# AT32A403Axx_v2 register map
Vendor: Keil; Series: AT32A403A; File version: 1.0
CPU: CM4 r0p1, little endian, no MPU, FPU, 4 interrupt priority bits
Registers are 32-bit, read-write, reset 0x0 unless marked. A register's access mark holds for its fields unless they carry their own. Offsets are from the block's base; [hi:lo] are bit positions; {n}, {i} and the like mark numbered series.

## NVIC — Nested Vectored Interrupt Controller
Base 0xE000E000
0x04 ICTR ro — Interrupt Controller Type Register
  [3:0] INTLINESNUM — Total number of interrupt lines in groups
0x100 ISER0 — Interrupt Set-Enable Register
  [31:0] SETENA
0x104 ISER1 — Interrupt Set-Enable Register
  [31:0] SETENA
0x180 ICER0 — Interrupt Clear-Enable Register
  [31:0] CLRENA
0x184 ICER1 — Interrupt Clear-Enable Register
  [31:0] CLRENA
0x200 ISPR0 — Interrupt Set-Pending Register
  [31:0] SETPEND
0x204 ISPR1 — Interrupt Set-Pending Register
  [31:0] SETPEND
0x280 ICPR0 — Interrupt Clear-Pending Register
  [31:0] CLRPEND
0x284 ICPR1 — Interrupt Clear-Pending Register
  [31:0] CLRPEND
0x300 IABR0 ro — Interrupt Active Bit Register
  [31:0] ACTIVE
0x304 IABR1 ro — Interrupt Active Bit Register
  [31:0] ACTIVE
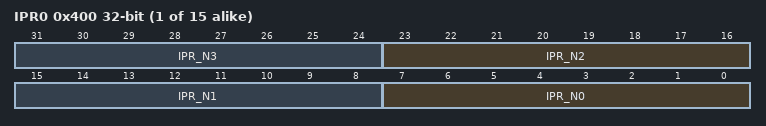
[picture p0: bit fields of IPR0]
{0x400+4i} IPR{i} (i=0..14) — Interrupt Priority Register
  [8n+7:8n] IPR_N{n} (n=0..3)
0xF00 STIR wo — Software Triggered Interrupt Register
  [8:0] INTID — interrupt to be triggered

## USBFS — Universal serial bus full-speed device interface
Base 0x40005C00
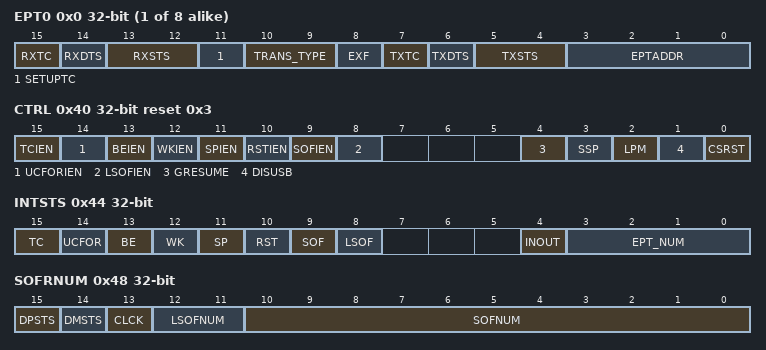
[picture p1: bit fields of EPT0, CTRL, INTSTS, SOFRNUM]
{0x0+4i} EPT{i} (i=0..7) — endpoint {i} register
  [15] RXTC — Rx transaction completed
  [14] RXDTS — Rx data toggle synchronization
  [13:12] RXSTS — Rx Status
  [11] SETUPTC — Setup transaction completed
  [10:9] TRANS_TYPE — Transfer type
  [8] EXF — Endpoint extend function
  [7] TXTC — Tx transaction completed
  [6] TXDTS — Tx data toggle synchronization
  [5:4] TXSTS — Tx status
  [3:0] EPTADDR — Endpoint address
0x40 CTRL reset 0x3 — control register
  [15] TCIEN — transmission completed interrupt enable
  [14] UCFORIEN — USB Core fifo overrun interrupt enable
  [13] BEIEN — Bus error interrupt enable
  [12] WKIEN — Wakeup/Remote wakeup interrupt enable
  [11] SPIEN — Bus suspend mode interrupt enable
  [10] RSTIEN — Bus reset interrupt enable
  [9] SOFIEN — Start of frame interrupt enable
  [8] LSOFIEN — Lost start of frame interrupt enable
  [4] GRESUME — Generate resume request
  [3] SSP — Soft suspend config
  [2] LPM — Low power mode
  [1] DISUSB — Disable usb phy
  [0] CSRST — Core soft reset
0x44 INTSTS — interrupt status register
  [15] TC — transaction completed
  [14] UCFOR — USB core fifo overrun memory
  [13] BE — Bus error
  [12] WK — Wakeup
  [11] SP — Bus suspend
  [10] RST — Bus reset
  [9] SOF — start of frame
  [8] LSOF — Lost start of frame
  [4] INOUT — In/Out transaction
  [3:0] EPT_NUM — Endpoint number
0x48 SOFRNUM — frame number register
  [15] DPSTS — DP status
  [14] DMSTS — DM status
  [13] CLCK — Connect locked
  [12:11] LSOFNUM — Lost start of frame number
  [10:0] SOFNUM — Start of frame number
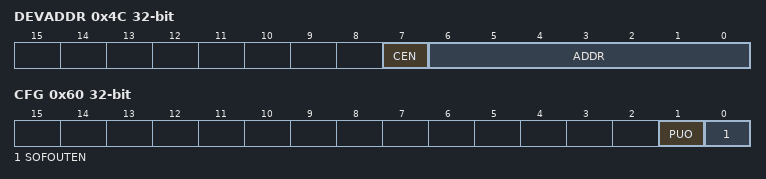
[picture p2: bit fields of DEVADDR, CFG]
0x4C DEVADDR — device address
  [7] CEN — USB core enable
  [6:0] ADDR — Host assign device address
0x50 BUFTBL — Buffer table address
  [15:3] BTADDR — Endpoint buffer table start address
0x60 CFG — CFG control register
  [1] PUO — DP pullup off
  [0] SOFOUTEN — SOF output enable

## ETHERNET_MMC — Ethernet: MAC management counters
Base 0x40028100
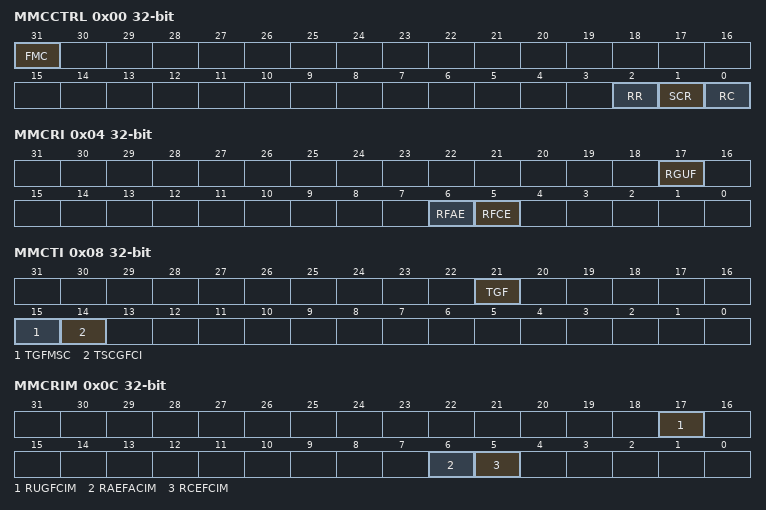
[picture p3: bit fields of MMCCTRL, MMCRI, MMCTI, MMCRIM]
0x00 MMCCTRL — Ethernet MMC control register
  [31] FMC — Freeze MMC counter
  [2] RR — Reset on read
  [1] SCR — Stop counter rollover
  [0] RC — Reset counter
0x04 MMCRI — Ethernet MMC receive interrupt register
  [17] RGUF — Received good unicast frames
  [6] RFAE — Received frames alignment error
  [5] RFCE — Received frames CRC error
0x08 MMCTI — Ethernet MMC transmit interrupt register
  [21] TGF — Transmitted good frames
  [15] TGFMSC — Transmit good frames more single collision
  [14] TSCGFCI — Transmit single collision good frame counter interrupt
0x0C MMCRIM — Ethernet MMC receive interrupt mask register
  [17] RUGFCIM — Received unicast good frame counter interrupt mask
  [6] RAEFACIM — Received alignment error frame alignment counter interrupt mask
  [5] RCEFCIM — Received CRC error frame counter interrupt mask
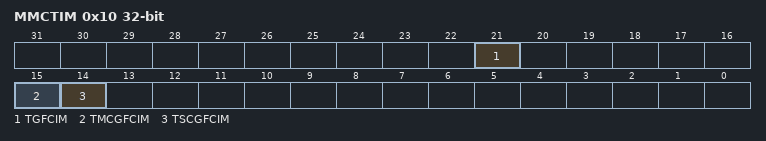
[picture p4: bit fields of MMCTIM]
0x10 MMCTIM — Ethernet MMC transmit interrupt mask register
  [21] TGFCIM — Transmitted good frame counter interrupt mask
  [15] TMCGFCIM — Transmit multiple collision good frame counter interrupt mask
  [14] TSCGFCIM — Transmit single collision good frame counter interrupt mask
0x4C MMCTFSCC ro — Ethernet MMC transmitted good frames after a single collision counter
  [31:0] TGFSCC — Transmitted good frames single collision counter
0x50 MMCTFMSCC ro — Ethernet MMC transmitted good frames after more than a single collision
  [31:0] TGFMSCC — Transmitted good frame more single collision counter
0x68 MMCTFCNT ro — Ethernet MMC transmitted good frames counter register
  [31:0] TGFC — Transmitted good frames counter
0x94 MMCRFCECNT ro — Ethernet MMC received frames with CRC error counter register
  [31:0] RFCEC — Received frames CRC error counter
0x98 MMCRFAECNT ro — Ethernet MMC received frames with alignment error counter register
  [31:0] RFAEC — Received frames alignment error counter
0xC4 MMCRGUFCNT ro — MMC received good unicast frames counter register
  [31:0] RGUFC — Received good unicast frames counter

## ETHERNET_PTP — Ethernet: Precision time protocol
Base 0x40028700
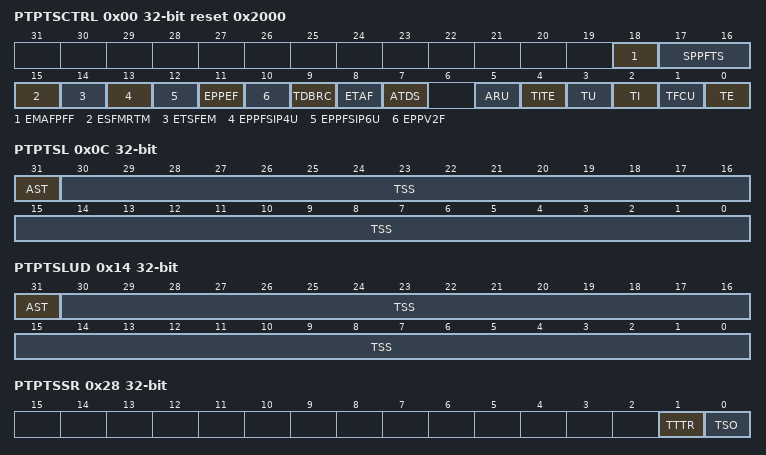
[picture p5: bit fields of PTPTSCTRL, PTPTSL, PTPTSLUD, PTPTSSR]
0x00 PTPTSCTRL reset 0x2000 — Ethernet PTP time stamp control register
  [18] EMAFPFF — Enable MAC address for PTP frame filtering
  [17:16] SPPFTS — Select PTP packet for taking snapshot
  [15] ESFMRTM — Enable snapshot for message relevant to master
  [14] ETSFEM — Enable timestamp snapshot for event message
  [13] EPPFSIP4U — Enable processing of PTP frames sent over IPv4-UDP
  [12] EPPFSIP6U — Enable processing of PTP frames sent over IPv6-UDP
  [11] EPPEF — Enable processing of PTP over EMAC frames
  [10] EPPV2F — Enable PTP packet processing for version2 format
  [9] TDBRC — Timestamp digital or binary rollover control
  [8] ETAF — Enable timestamp for all frames
  [7] ATDS — Alternate dma descriptor size
  [5] ARU — Addend register update
  [4] TITE — Timestamp interrupt trigger enable
  [3] TU — Timestamp update
  [2] TI — Timestamp initialize
  [1] TFCU — Timestamp fine or coarse update
  [0] TE — Timestamp enable
0x04 PTPSSINC — Ethernet PTP subsecond increment register
  [7:0] SSIV — Sub-second increment value
0x08 PTPTSH ro — Ethernet PTP time stamp high register
  [31:0] TS — Timestamp second
0x0C PTPTSL ro — Ethernet PTP time stamp low register
  [31] AST — Add or subtract time
  [30:0] TSS — Timestamp subseconds
0x10 PTPTSHUD — Ethernet PTP time stamp high update register
  [31:0] TS — Timestamp second
0x14 PTPTSLUD — Ethernet PTP time stamp low update register
  [31] AST — Add or subtract time
  [30:0] TSS — Timestamp subseconds
0x18 PTPTSAD — Ethernet PTP time stamp addend register
  [31:0] TAR — Timestamp addend register
0x1C PTPTTH — Ethernet PTP target time high register
  [31:0] TTSR — Target time seconds register
0x20 PTPTTL — Ethernet PTP target time low register
  [31:0] TTLR — Target timestamp low register
0x28 PTPTSSR ro — Ethernet PTP time stamp status register
  [1] TTTR — Timestamp target time reached
  [0] TSO — Timestamp second overflow
0x2C PTPPPSCR ro — Ethernet PTP PPS control register
  [3:0] POFC — PPS Output frequency control
